# N32G033 register map
Vendor: Nsingtech Ltd.; File version: 1.0
Registers are 32-bit, read-write, reset 0x0 unless marked. A register's access mark holds for its fields unless they carry their own. Offsets are from the block's base; lines under a group give offsets from that group; [hi:lo] are bit positions; {n}, {i} and the like mark numbered series; 'fields as' and 'values as' point back to an identical list; <NAME> marks a mode.

## Memory map
0x40000400 TIM3 size 0x400
0x40001000 TIM6 size 0x400
0x40002000 OPAMP size 0x400
0x40002400 COMP size 0x400
0x40003000 IWDG size 0x400
0x40004400 UART2 size 0x400
0x40004800 UART3 size 0x400
0x40005400 I2C1 size 0x400
0x40005800 I2C2 size 0x400
0x40007000 PWR size 0x400
0x40010400 EXTI size 0x400
0x40012000 SPI1 size 0x400
0x40012C00 TIM1 size 0x400 — TIM
0x40013400 TIM4 size 0x400
0x40013800 UART1 size 0x400
0x40014400 SPI2 size 0x400
0x40020000 DMA size 0x400
0x40020400 SQRT size 0x400
0x40020800 ADC size 0x400
0x40021000 RCC size 0x400
0x40022000 FLASH size 0x400 — interal FLASH controller
0x40023000 GPIO size 0x400
0x40028000 HDIV size 0x400

## Interrupts
0 PVD (PWR) — PVD interrupt
1 FLASH — FLASH interrupt
2 EXTI0_6 (EXTI) — EXTI0_6 global interrupt
3 COMP — COMP global interrupt
4 UART1 — UART1 global interrupt
5 UART2 — UART2 interrupt
6 TIM1_BRK_UP_TRG_COM (TIM1) — TIM1_BRK_UP_TRG_COM global interrupt
7 TIM1_CC (TIM1) — TIM1_CC global interrupt
8 ADC — ADC global interrupt
9 SPI1 — SPI1 global interrupt
10 IWDG — IWDG global interrupt
11 TIM4 — TIM4 global interrupt
12 TIM3 — TIM3 global interrupt
13 TIM6 — TIM6 global interrupt
14 UART3 — UART3 interrupt
15 SPI2 — SPI2 interrupt
16 I2C1_EV (I2C1) — I2C1 EV interrupt
17 I2C1_ER (I2C1) — I2C1 ER interrupt
20 DMA — DMA global interrupt
25 I2C2_EV (I2C2) — I2C2 EV interrupt
26 I2C2_ER (I2C2) — I2C2 ER interrupt

## ADC
Base 0x40020800
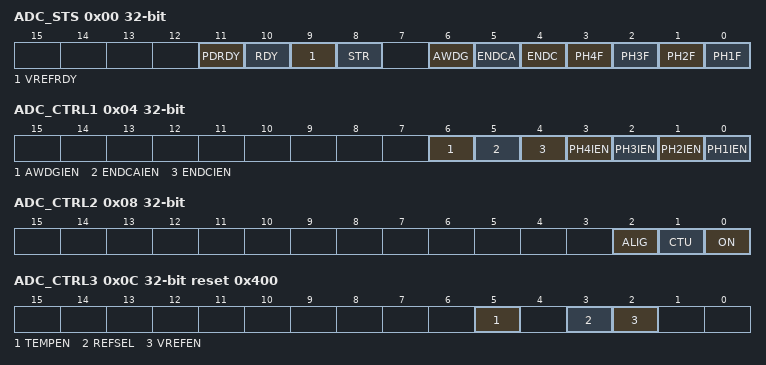
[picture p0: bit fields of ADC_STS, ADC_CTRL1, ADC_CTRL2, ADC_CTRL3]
0x00 ADC_STS — ADC status register
  [11] PDRDY, [10] RDY, [9] VREFRDY, [8] STR, [6] AWDG, [5] ENDCA, [4] ENDC, [n-1] PH{n}F (n=1..4)
0x04 ADC_CTRL1 — ADC control register 1
  [6] AWDGIEN, [5] ENDCAIEN, [4] ENDCIEN, [n-1] PH{n}IEN (n=1..4)
0x08 ADC_CTRL2 — ADC control register 2
  [2] ALIG, [1] CTU, [0] ON
0x0C ADC_CTRL3 reset 0x400 — ADC control register 3
  [5] TEMPEN, [3] REFSEL, [2] VREFEN
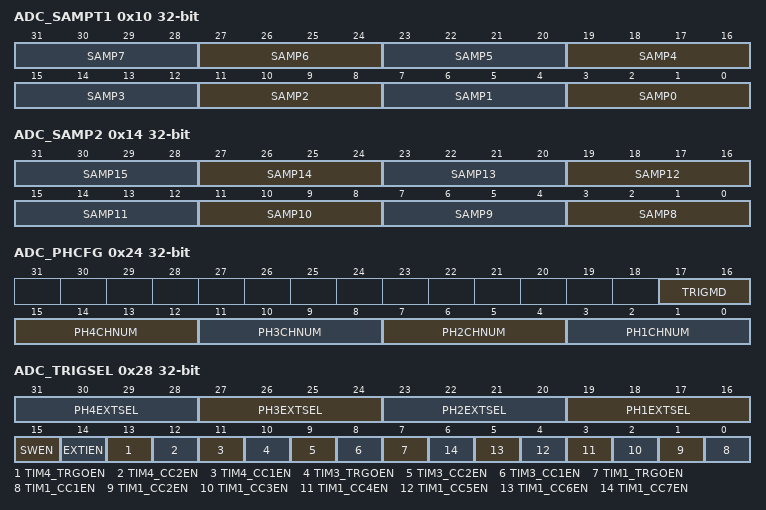
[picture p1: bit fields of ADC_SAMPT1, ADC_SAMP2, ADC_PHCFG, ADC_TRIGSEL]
0x10 ADC_SAMPT1 — sample time register 1
  [4n+3:4n] SAMP{n} (n=0..7)
0x14 ADC_SAMP2 — sample time register 2
  [4n-29:4n-32] SAMP{n} (n=8..15)
0x18 ADC_AWDHIGH reset 0xFFF — ADC watchdog high threshold register
  [11:0] HTH
0x1C ADC_AWDLOW — ADC watchdog low threshold register
  [11:0] LTH
0x20 ADC_AWDEN — ADC data register 4
  [9:0] AWDENx
0x24 ADC_PHCFG — ADC segment configuration register
  [17:16] TRIGMD, [4n-1:4n-4] PH{n}CHNUM (n=1..4)
0x28 ADC_TRIGSEL — nan
  [4n+15:4n+12] PH{n}EXTSEL (n=1..4), [15] SWEN, [14] EXTIEN, [13] TIM4_TRGOEN, [12] TIM4_CC2EN, [11] TIM4_CC1EN, [10] TIM3_TRGOEN, [9] TIM3_CC2EN, [8] TIM3_CC1EN, [7] TIM1_TRGOEN, [n-1] TIM1_CC{n}EN (n=1..7)
0x2C ADC_PHSWTRIG — ADC control register 2
  [15:0] PHSWSTART
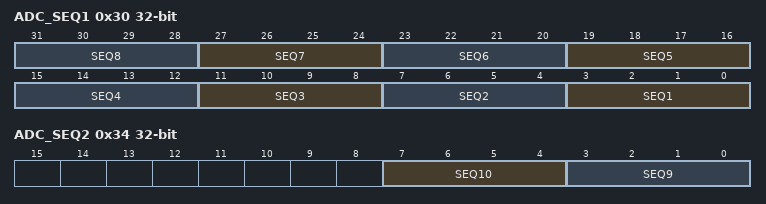
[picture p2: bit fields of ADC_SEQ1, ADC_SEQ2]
0x30 ADC_SEQ1 — ADC seqence register 1
  [4n-1:4n-4] SEQ{n} (n=1..8)
0x34 ADC_SEQ2 — ADC seqence register 2
  [7:4] SEQ10, [3:0] SEQ9
{0x38+4i} ADC_DAT{i} (i=0..9) — ADC data register {i}
  [15:0] DAT{i}

## COMP
Base 0x40002400
0x00 COMP_INTEN — nan
  [0] CMPIEN
0x04 COMP_INTSTS — nan
  [0] CMPIS
0x0C COMP_LOCK — nan
  [0] CMPLK
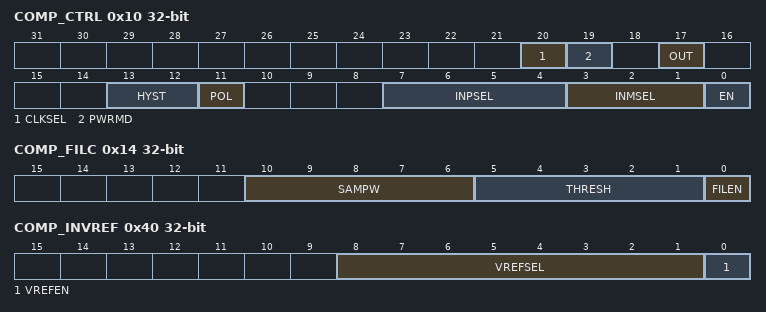
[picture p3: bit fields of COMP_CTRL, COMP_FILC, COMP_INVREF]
0x10 COMP_CTRL — nan
  [20] CLKSEL, [19] PWRMD, [17] OUT, [13:12] HYST, [11] POL, [7:4] INPSEL, [3:1] INMSEL, [0] EN
0x14 COMP_FILC — nan
  [10:6] SAMPW, [5:1] THRESH, [0] FILEN
0x18 COMP_FILP — nan
  [15:0] CLKPSC
0x40 COMP_INVREF — nan
  [8:1] VREFSEL, [0] VREFEN

## DMA
Base 0x40020000
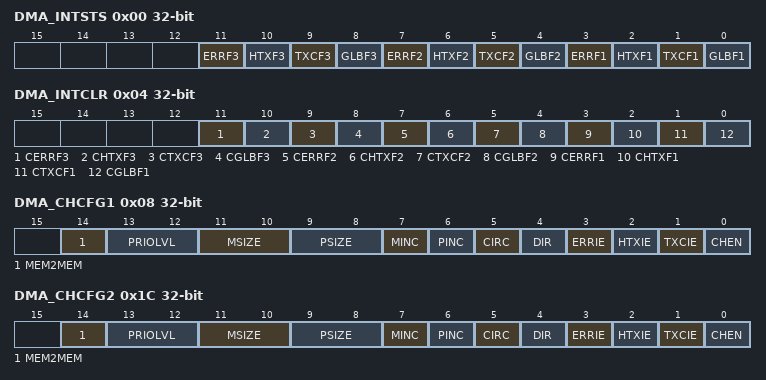
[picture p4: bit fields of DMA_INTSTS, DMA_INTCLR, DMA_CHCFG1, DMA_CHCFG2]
0x00 DMA_INTSTS — DMA Interrupt Status Register
  [11] ERRF3, [10] HTXF3, [9] TXCF3, [8] GLBF3, [7] ERRF2, [6] HTXF2, [5] TXCF2, [4] GLBF2, [3] ERRF1, [2] HTXF1, [1] TXCF1, [0] GLBF1
0x04 DMA_INTCLR — DMA Interrupt Flag Clear Register
  [11] CERRF3, [10] CHTXF3, [9] CTXCF3, [8] CGLBF3, [7] CERRF2, [6] CHTXF2, [5] CTXCF2, [4] CGLBF2, [3] CERRF1, [2] CHTXF1, [1] CTXCF1, [0] CGLBF1
0x08 DMA_CHCFG1 — DMA channel 1 configuration register
  [14] MEM2MEM, [13:12] PRIOLVL, [11:10] MSIZE, [9:8] PSIZE, [7] MINC, [6] PINC, [5] CIRC, [4] DIR, [3] ERRIE, [2] HTXIE, [1] TXCIE, [0] CHEN
0x0C DMA_TXNUM1 — DMA channel 1 transfer number register
  [15:0] NDTX
0x10 DMA_PADDR1 — DMA channel 1 peripheral address register
  [31:0] ADDR
{0x0+0x14*i} DMA_MADDR{i} (i=1..3) — DMA channel {i} memory address register
  [31:0] ADDR
0x18 DMA_CHSEL1 — DMA channel 1 channel request select register
  [5:0] CH_SEL
0x1C DMA_CHCFG2 — DMA channel 2 configuration register
  fields as DMA_CHCFG1
0x20 DMA_TXNUM2 — DMA channel 2 transfer number register
  [15:0] NDTX
0x24 DMA_PADDR2 — DMA channel 2 peripheral address register
  [31:0] ADDR
0x2C DMA_CHSEL2 — DMA channel 2 channel request select register
  [5:0] CH_SEL
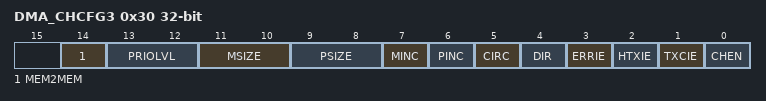
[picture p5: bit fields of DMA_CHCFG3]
0x30 DMA_CHCFG3 — DMA channel 3 configuration register
  fields as DMA_CHCFG1
0x34 DMA_TXNUM3 — DMA channel 3 transfer number register
  [15:0] NDTX
0x38 DMA_PADDR3 — DMA channel 3 peripheral address register
  [31:0] ADDR
0x40 DMA_CHSEL3 — nan
  [5:0] CH_SEL
